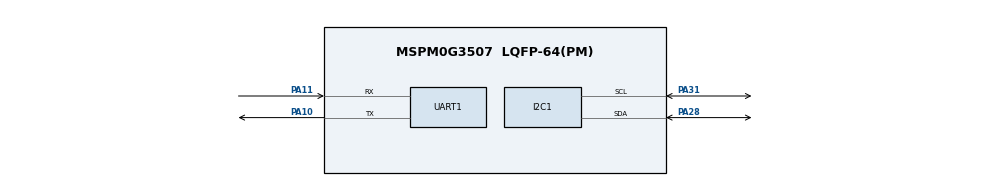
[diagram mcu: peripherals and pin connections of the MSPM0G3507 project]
/**
 * These arguments were used when this file was generated. They will be automatically applied on subsequent loads
 * via the GUI or CLI. Run CLI with '--help' for additional information on how to override these arguments.
 * @cliArgs --device "MSPM0G350X" --part "Default" --package "LQFP-64(PM)" --product "mspm0_sdk@2.10.00.04"
 * @v2CliArgs --device "MSPM0G3507" --package "LQFP-64(PM)" --product "mspm0_sdk@2.10.00.04"
 * @versions {"tool":"1.26.2+4477"}
 */

/**
 * Import the modules used in this configuration.
 */
const GPIO   = scripting.addModule("/ti/driverlib/GPIO", {}, false);
const GPIO1  = GPIO.addInstance();
const SYSCTL = scripting.addModule("/ti/driverlib/SYSCTL");
const TIMER  = scripting.addModule("/ti/driverlib/TIMER", {}, false);
const TIMER1 = TIMER.addInstance();
const UART   = scripting.addModule("/ti/driverlib/UART", {}, false);
const UART1  = UART.addInstance();
const I2C    = scripting.addModule("/ti/driverlib/I2C", {}, false);
const I2C1   = I2C.addInstance();

/**
 * Clock: 40 MHz HFXT → 80 MHz CPUCLK via SYSPLL
 */
const divider9       = system.clockTree["UDIV"];
divider9.divideValue = 2;

const gate7  = system.clockTree["MFCLKGATE"];
gate7.enable = true;

const multiplier2         = system.clockTree["PLL_QDIV"];
multiplier2.multiplyValue = 4;

const mux4       = system.clockTree["EXHFMUX"];
mux4.inputSelect = "EXHFMUX_XTAL";

const mux8       = system.clockTree["HSCLKMUX"];
mux8.inputSelect = "HSCLKMUX_SYSPLL0";

const mux12       = system.clockTree["SYSPLLMUX"];
mux12.inputSelect = "zSYSPLLMUX_HFCLK";

const hfxt        = system.clockTree["HFXT"];
hfxt.inputFreq    = 40;
hfxt.enable       = true;
hfxt.HFXTStartup  = 10;
hfxt.HFCLKMonitor = true;

SYSCTL.forceDefaultClkConfig = true;
SYSCTL.clockTreeEn           = true;

/**
 * GPIO: PB22 as LED output
 */
GPIO1.$name                         = "LED";
GPIO1.port                          = "PORTB";
GPIO1.associatedPins[0].$name       = "PIN_22";
GPIO1.associatedPins[0].assignedPin = "22";

/**
 * TIMG12: 1 ms periodic timer for LED blinking
 */
TIMER1.$name              = "TIMER_0";
TIMER1.timerPeriod        = "1 ms";
TIMER1.timerMode          = "PERIODIC";
TIMER1.interrupts         = ["ZERO"];
TIMER1.peripheral.$assign = "TIMG12";

/**
 * UART0: PA10 TX, PA11 RX, 115200 baud, RX interrupt for echo
 */
UART1.$name                    = "UART_0";
UART1.targetBaudRate           = 115200;
UART1.enabledInterrupts        = ["RX"];
UART1.peripheral.rxPin.$assign = "PA11";
UART1.peripheral.txPin.$assign = "PA10";
UART1.txPinConfig.$name        = "ti_driverlib_gpio_GPIOPinGeneric0";
UART1.rxPinConfig.$name        = "ti_driverlib_gpio_GPIOPinGeneric1";

/**
 * I2C0: PA28 SDA, PA31 SCL, Controller 模式, 标准速度 100kHz (接 SSD1306 OLED)
 */
I2C1.$name                              = "I2C_0";
I2C1.basicEnableController              = true;
I2C1.basicClockSource                   = "BUSCLK";
I2C1.basicClockSourceDivider            = 1;
I2C1.basicControllerStandardBusSpeed    = "Standard";
I2C1.basicEnableController10BitAddress  = false;
I2C1.peripheral.$assign                 = "I2C0";
I2C1.peripheral.sdaPin.$assign          = "PA28";
I2C1.peripheral.sclPin.$assign          = "PA31";

/**
 * Board: debug interface
 */
const Board = scripting.addModule("/ti/driverlib/Board", {}, false);

/**
 * Pinmux solution for unlocked pins/peripherals. This ensures that minor changes to the automatic solver in a future
 * version of the tool will not impact the pinmux you originally saw.  These lines can be completely deleted in order to
 * re-solve from scratch.
 */
hfxt.peripheral.$suggestSolution           = "SYSCTL";
hfxt.peripheral.hfxInPin.$suggestSolution  = "PA5";
hfxt.peripheral.hfxOutPin.$suggestSolution = "PA6";
GPIO1.associatedPins[0].pin.$suggestSolution = "PB22";
Board.peripheral.$suggestSolution            = "DEBUGSS";
Board.peripheral.swclkPin.$suggestSolution   = "PA20";
Board.peripheral.swdioPin.$suggestSolution   = "PA19";
UART1.peripheral.$suggestSolution            = "UART0";
I2C1.peripheral.$suggestSolution               = "I2C0";
I2C1.peripheral.sdaPin.$suggestSolution         = "PA28";
I2C1.peripheral.sclPin.$suggestSolution         = "PA31";
